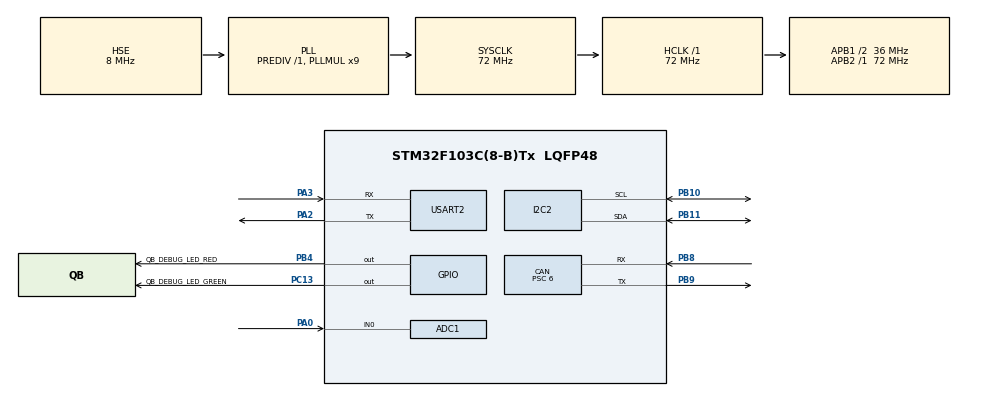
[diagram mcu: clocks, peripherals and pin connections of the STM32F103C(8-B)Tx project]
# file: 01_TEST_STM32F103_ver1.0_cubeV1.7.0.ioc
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ADC1.Channel-0\#ChannelRegularConversion=ADC_CHANNEL_0
ADC1.NbrOfConversionFlag=1
ADC1.Rank-0\#ChannelRegularConversion=1
ADC1.SamplingTime-0\#ChannelRegularConversion=ADC_SAMPLETIME_1CYCLE_5
ADC1.master=1
CAN.ABOM=ENABLE
CAN.BS1=CAN_BS1_10TQ
CAN.CalculateTimeBit=2000
CAN.CalculateTimeQuantum=166.66666666666669
CAN.Prescaler=6
I2C2.I2C_Mode=I2C_Fast
Mcu.Family=STM32F1
Mcu.Name=STM32F103C(8-B)Tx
Mcu.Package=LQFP48
Mcu.UserConstants=USART2_BAUND,9600
NVIC.PriorityGroup=NVIC_PRIORITYGROUP_4
NVIC.TIM1_UP_IRQn=true\:0\:0\:false\:false\:true\:false
NVIC.TimeBase=TIM1_UP_IRQn
NVIC.TimeBaseIP=TIM1
NVIC.USB_LP_CAN1_RX0_IRQn=true\:0\:0\:false\:false\:true\:false
PA0-WKUP.Signal=ADCx_IN0
PA11.Signal=USB_DM
PA12.Signal=USB_DP
PA13.Mode=Serial_Wire
PA13.Signal=SYS_JTMS-SWDIO
PA14.Mode=Serial_Wire
PA14.Signal=SYS_JTCK-SWCLK
PA2.Mode=Asynchronous
PA2.Signal=USART2_TX
PA3.Mode=Asynchronous
PA3.Signal=USART2_RX
PB10.Mode=I2C
PB10.Signal=I2C2_SCL
PB11.Mode=I2C
PB11.Signal=I2C2_SDA
PB4.GPIO_Label=QB_DEBUG_LED_RED
PB4.Signal=GPIO_Output
PB6.Signal=I2C1_SCL
PB7.Signal=I2C1_SDA
PB8.Mode=Master
PB8.Signal=CAN_RX
PB9.Mode=Master
PB9.Signal=CAN_TX
PC13-TAMPER-RTC.GPIO_Label=QB_DEBUG_LED_GREEN
PC13-TAMPER-RTC.Signal=GPIO_Output
PD0-OSC_IN.Mode=HSE-External-Oscillator
PD0-OSC_IN.Signal=RCC_OSC_IN
PD1-OSC_OUT.Mode=HSE-External-Oscillator
PD1-OSC_OUT.Signal=RCC_OSC_OUT
ProjectManager.HeapSize=0x200
ProjectManager.StackSize=0x400
ProjectManager.TargetToolchain=TrueSTUDIO
RCC.ADCPresc=RCC_ADCPCLK2_DIV6
RCC.AHBFreq_Value=72000000
RCC.APB1CLKDivider=RCC_HCLK_DIV2
RCC.APB1Freq_Value=36000000
RCC.APB1TimFreq_Value=72000000
RCC.APB2Freq_Value=72000000
RCC.APB2TimFreq_Value=72000000
RCC.HCLKFreq_Value=72000000
RCC.PLLMUL=RCC_PLL_MUL9
RCC.PLLSourceVirtual=RCC_PLLSOURCE_HSE
RCC.SYSCLKFreq_VALUE=72000000
RCC.SYSCLKSource=RCC_SYSCLKSOURCE_PLLCLK
RCC.USBFreq_Value=48000000
RCC.USBPrescaler=RCC_USBCLKSOURCE_PLL_DIV1_5
SH.ADCx_IN0.0=ADC1_IN0,IN0
USART2.BaudRate=USART2_BAUND
USART2.VirtualMode=VM_ASYNC
VP_SYS_VS_tim1.Mode=TIM1
board=custom

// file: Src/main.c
/* USER CODE BEGIN Header */
/**
  ******************************************************************************
  * @file           : main.c
  * @brief          : Main program body
  ******************************************************************************
  * This notice applies to any and all portions of this file
  * that are not between comment pairs USER CODE BEGIN and
  * USER CODE END. Other portions of this file, whether
  * inserted by the user or by software development tools
  * are owned by their respective copyright owners.
  *
  * Copyright (c) 2018 STMicroelectronics International N.V.
  * All rights reserved.
  *
  * Redistribution and use in source and binary forms, with or without
  * modification, are permitted, provided that the following conditions are met:
  *
  * 1. Redistribution of source code must retain the above copyright notice,
  *    this list of conditions and the following disclaimer.
  * 2. Redistributions in binary form must reproduce the above copyright notice,
  *    this list of conditions and the following disclaimer in the documentation
  *    and/or other materials provided with the distribution.
  * 3. Neither the name of STMicroelectronics nor the names of other
  *    contributors to this software may be used to endorse or promote products
  *    derived from this software without specific written permission.
  * 4. This software, including modifications and/or derivative works of this
  *    software, must execute solely and exclusively on microcontroller or
  *    microprocessor devices manufactured by or for STMicroelectronics.
  * 5. Redistribution and use of this software other than as permitted under
  *    this license is void and will automatically terminate your rights under
  *    this license.
  *
  * THIS SOFTWARE IS PROVIDED BY STMICROELECTRONICS AND CONTRIBUTORS "AS IS"
  * AND ANY EXPRESS, IMPLIED OR STATUTORY WARRANTIES, INCLUDING, BUT NOT
  * LIMITED TO, THE IMPLIED WARRANTIES OF MERCHANTABILITY, FITNESS FOR A
  * PARTICULAR PURPOSE AND NON-INFRINGEMENT OF THIRD PARTY INTELLECTUAL PROPERTY
  * RIGHTS ARE DISCLAIMED TO THE FULLEST EXTENT PERMITTED BY LAW. IN NO EVENT
  * SHALL STMICROELECTRONICS OR CONTRIBUTORS BE LIABLE FOR ANY DIRECT, INDIRECT,
  * INCIDENTAL, SPECIAL, EXEMPLARY, OR CONSEQUENTIAL DAMAGES (INCLUDING, BUT NOT
  * LIMITED TO, PROCUREMENT OF SUBSTITUTE GOODS OR SERVICES; LOSS OF USE, DATA,
  * OR PROFITS; OR BUSINESS INTERRUPTION) HOWEVER CAUSED AND ON ANY THEORY OF
  * LIABILITY, WHETHER IN CONTRACT, STRICT LIABILITY, OR TORT (INCLUDING
  * NEGLIGENCE OR OTHERWISE) ARISING IN ANY WAY OUT OF THE USE OF THIS SOFTWARE,
  * EVEN IF ADVISED OF THE POSSIBILITY OF SUCH DAMAGE.
  *
  ******************************************************************************
  */
/* USER CODE END Header */

#include "main.h"

ADC_HandleTypeDef hadc1;

CAN_HandleTypeDef hcan;

I2C_HandleTypeDef hi2c2;

UART_HandleTypeDef huart2;

void SystemClock_Config(void);
static void MX_GPIO_Init(void);
static void MX_ADC1_Init(void);
static void MX_USART2_UART_Init(void);
static void MX_I2C2_Init(void);
static void MX_CAN_Init(void);

int main(void)
{

  /* MCU Configuration--------------------------------------------------------*/

  /* Reset of all peripherals, Initializes the Flash interface and the Systick. */
  HAL_Init();

  /* Configure the system clock */
  SystemClock_Config();

  /* Initialize all configured peripherals */
  MX_GPIO_Init();
  MX_ADC1_Init();
  MX_USART2_UART_Init();
  MX_I2C2_Init();
  MX_CAN_Init();

  /* Infinite loop */
  /* USER CODE BEGIN WHILE */
  while (1)
  {
#if 0
	  HAL_Delay(200);
	  HAL_GPIO_TogglePin(QB_DEBUG_LED_GREEN_GPIO_Port, QB_DEBUG_LED_GREEN_Pin);
	  HAL_Delay(100);
	  HAL_GPIO_TogglePin(QB_DEBUG_LED_GREEN_GPIO_Port, QB_DEBUG_LED_GREEN_Pin);
#endif
    /* USER CODE END WHILE */

  }
}

void SystemClock_Config(void)
{
  RCC_OscInitTypeDef RCC_OscInitStruct = {0};
  RCC_ClkInitTypeDef RCC_ClkInitStruct = {0};
  RCC_PeriphCLKInitTypeDef PeriphClkInit = {0};

  /**Initializes the CPU, AHB and APB busses clocks
  */
  RCC_OscInitStruct.OscillatorType = RCC_OSCILLATORTYPE_HSE;
  RCC_OscInitStruct.HSEState = RCC_HSE_ON;
  RCC_OscInitStruct.HSEPredivValue = RCC_HSE_PREDIV_DIV1;
  RCC_OscInitStruct.HSIState = RCC_HSI_ON;
  RCC_OscInitStruct.PLL.PLLState = RCC_PLL_ON;
  RCC_OscInitStruct.PLL.PLLSource = RCC_PLLSOURCE_HSE;
  RCC_OscInitStruct.PLL.PLLMUL = RCC_PLL_MUL9;
  if (HAL_RCC_OscConfig(&RCC_OscInitStruct) != HAL_OK)
  {
    Error_Handler();
  }
  /**Initializes the CPU, AHB and APB busses clocks
  */
  RCC_ClkInitStruct.ClockType = RCC_CLOCKTYPE_HCLK|RCC_CLOCKTYPE_SYSCLK
                              |RCC_CLOCKTYPE_PCLK1|RCC_CLOCKTYPE_PCLK2;
  RCC_ClkInitStruct.SYSCLKSource = RCC_SYSCLKSOURCE_PLLCLK;
  RCC_ClkInitStruct.AHBCLKDivider = RCC_SYSCLK_DIV1;
  RCC_ClkInitStruct.APB1CLKDivider = RCC_HCLK_DIV2;
  RCC_ClkInitStruct.APB2CLKDivider = RCC_HCLK_DIV1;

  if (HAL_RCC_ClockConfig(&RCC_ClkInitStruct, FLASH_LATENCY_2) != HAL_OK)
  {
    Error_Handler();
  }
  PeriphClkInit.PeriphClockSelection = RCC_PERIPHCLK_ADC;
  PeriphClkInit.AdcClockSelection = RCC_ADCPCLK2_DIV6;
  if (HAL_RCCEx_PeriphCLKConfig(&PeriphClkInit) != HAL_OK)
  {
    Error_Handler();
  }
}

static void MX_ADC1_Init(void)
{

  ADC_ChannelConfTypeDef sConfig = {0};

  /**Common config
  */
  hadc1.Instance = ADC1;
  hadc1.Init.ScanConvMode = ADC_SCAN_DISABLE;
  hadc1.Init.ContinuousConvMode = DISABLE;
  hadc1.Init.DiscontinuousConvMode = DISABLE;
  hadc1.Init.ExternalTrigConv = ADC_SOFTWARE_START;
  hadc1.Init.DataAlign = ADC_DATAALIGN_RIGHT;
  hadc1.Init.NbrOfConversion = 1;
  if (HAL_ADC_Init(&hadc1) != HAL_OK)
  {
    Error_Handler();
  }
  /**Configure Regular Channel
  */
  sConfig.Channel = ADC_CHANNEL_0;
  sConfig.Rank = ADC_REGULAR_RANK_1;
  sConfig.SamplingTime = ADC_SAMPLETIME_1CYCLE_5;
  if (HAL_ADC_ConfigChannel(&hadc1, &sConfig) != HAL_OK)
  {
    Error_Handler();
  }

}

static void MX_CAN_Init(void)
{

  hcan.Instance = CAN1;
  hcan.Init.Prescaler = 6;
  hcan.Init.Mode = CAN_MODE_NORMAL;
  hcan.Init.SyncJumpWidth = CAN_SJW_1TQ;
  hcan.Init.TimeSeg1 = CAN_BS1_10TQ;
  hcan.Init.TimeSeg2 = CAN_BS2_1TQ;
  hcan.Init.TimeTriggeredMode = DISABLE;
  hcan.Init.AutoBusOff = ENABLE;
  hcan.Init.AutoWakeUp = DISABLE;
  hcan.Init.AutoRetransmission = DISABLE;
  hcan.Init.ReceiveFifoLocked = DISABLE;
  hcan.Init.TransmitFifoPriority = DISABLE;
  if (HAL_CAN_Init(&hcan) != HAL_OK)
  {
    Error_Handler();
  }

}

static void MX_I2C2_Init(void)
{

  hi2c2.Instance = I2C2;
  hi2c2.Init.ClockSpeed = 400000;
  hi2c2.Init.DutyCycle = I2C_DUTYCYCLE_2;
  hi2c2.Init.OwnAddress1 = 0;
  hi2c2.Init.AddressingMode = I2C_ADDRESSINGMODE_7BIT;
  hi2c2.Init.DualAddressMode = I2C_DUALADDRESS_DISABLE;
  hi2c2.Init.OwnAddress2 = 0;
  hi2c2.Init.GeneralCallMode = I2C_GENERALCALL_DISABLE;
  hi2c2.Init.NoStretchMode = I2C_NOSTRETCH_DISABLE;
  if (HAL_I2C_Init(&hi2c2) != HAL_OK)
  {
    Error_Handler();
  }

}

static void MX_USART2_UART_Init(void)
{

  huart2.Instance = USART2;
  huart2.Init.BaudRate = USART2_BAUND;
  huart2.Init.WordLength = UART_WORDLENGTH_8B;
  huart2.Init.StopBits = UART_STOPBITS_1;
  huart2.Init.Parity = UART_PARITY_NONE;
  huart2.Init.Mode = UART_MODE_TX_RX;
  huart2.Init.HwFlowCtl = UART_HWCONTROL_NONE;
  huart2.Init.OverSampling = UART_OVERSAMPLING_16;
  if (HAL_UART_Init(&huart2) != HAL_OK)
  {
    Error_Handler();
  }

}

static void MX_GPIO_Init(void)
{
  GPIO_InitTypeDef GPIO_InitStruct = {0};

  /* GPIO Ports Clock Enable */
  __HAL_RCC_GPIOC_CLK_ENABLE();
  __HAL_RCC_GPIOD_CLK_ENABLE();
  __HAL_RCC_GPIOA_CLK_ENABLE();
  __HAL_RCC_GPIOB_CLK_ENABLE();

  /*Configure GPIO pin Output Level */
  HAL_GPIO_WritePin(QB_DEBUG_LED_GREEN_GPIO_Port, QB_DEBUG_LED_GREEN_Pin, GPIO_PIN_RESET);

  /*Configure GPIO pin Output Level */
  HAL_GPIO_WritePin(QB_DEBUG_LED_RED_GPIO_Port, QB_DEBUG_LED_RED_Pin, GPIO_PIN_RESET);

  /*Configure GPIO pin : QB_DEBUG_LED_GREEN_Pin */
  GPIO_InitStruct.Pin = QB_DEBUG_LED_GREEN_Pin;
  GPIO_InitStruct.Mode = GPIO_MODE_OUTPUT_PP;
  GPIO_InitStruct.Pull = GPIO_NOPULL;
  GPIO_InitStruct.Speed = GPIO_SPEED_FREQ_LOW;
  HAL_GPIO_Init(QB_DEBUG_LED_GREEN_GPIO_Port, &GPIO_InitStruct);

  /*Configure GPIO pin : QB_DEBUG_LED_RED_Pin */
  GPIO_InitStruct.Pin = QB_DEBUG_LED_RED_Pin;
  GPIO_InitStruct.Mode = GPIO_MODE_OUTPUT_PP;
  GPIO_InitStruct.Pull = GPIO_NOPULL;
  GPIO_InitStruct.Speed = GPIO_SPEED_FREQ_LOW;
  HAL_GPIO_Init(QB_DEBUG_LED_RED_GPIO_Port, &GPIO_InitStruct);

  /*Configure GPIO pins : PB6 PB7 */
  GPIO_InitStruct.Pin = GPIO_PIN_6|GPIO_PIN_7;
  GPIO_InitStruct.Mode = GPIO_MODE_AF_OD;
  GPIO_InitStruct.Speed = GPIO_SPEED_FREQ_HIGH;
  HAL_GPIO_Init(GPIOB, &GPIO_InitStruct);

}

void HAL_TIM_PeriodElapsedCallback(TIM_HandleTypeDef *htim)
{
  /* USER CODE BEGIN Callback 0 */
	if (htim->Instance == TIM1) {
		static uint32_t tim_cnt = 50;
		tim_cnt--;
		if( !tim_cnt )
		{
			tim_cnt = 50;
			HAL_GPIO_TogglePin(QB_DEBUG_LED_GREEN_GPIO_Port,QB_DEBUG_LED_GREEN_Pin);
			HAL_GPIO_TogglePin(QB_DEBUG_LED_RED_GPIO_Port,QB_DEBUG_LED_RED_Pin);
		}
	}
  /* USER CODE END Callback 0 */
  if (htim->Instance == TIM1) {
    HAL_IncTick();
  }
}

void Error_Handler(void)
{
}

/************************ (C) COPYRIGHT STMicroelectronics *****END OF FILE****/
